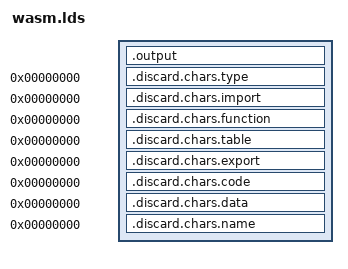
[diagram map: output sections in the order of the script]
SECTIONS
{
  .output : {
    LONG(0x6d736100)
    LONG(11)
    wasm-headers.o(.wasm.header.type); BYTE((((__wasm_type_payload_end - __wasm_type_payload)>>0*7)&0x7f)|0x80); BYTE((((__wasm_type_payload_end - __wasm_type_payload)>>1*7)&0x7f)|0x80); BYTE((((__wasm_type_payload_end - __wasm_type_payload)>>2*7)&0x7f)|0x80); BYTE((((__wasm_type_payload_end - __wasm_type_payload)>>3*7)&0x7f)|0x80); BYTE((((__wasm_type_payload_end - __wasm_type_payload)>>4*7)&0x7f)|0x80); BYTE((((__wasm_type_payload_end - __wasm_type_payload)>>5*7)&0x7f)|0x80); BYTE((((__wasm_type_payload_end - __wasm_type_payload)>>6*7)&0x7f)|0x80); BYTE((((__wasm_type_payload_end - __wasm_type_payload)>>7*7)&0x7f)|0x80); BYTE((((__wasm_type_payload_end - __wasm_type_payload)>>8*7)&0x7f)|0x80); BYTE((((__wasm_type_payload_end - __wasm_type_payload)>>9*7)&0x7f)|0x80); BYTE(0x80); BYTE(0x80); BYTE(0x80); BYTE(0x80); BYTE(0x80); BYTE(0x00);; __wasm_type_payload = .; BYTE((((__wasm_chars_type_end - __wasm_chars_type)>>0*7)&0x7f)|0x80); BYTE((((__wasm_chars_type_end - __wasm_chars_type)>>1*7)&0x7f)|0x80); BYTE((((__wasm_chars_type_end - __wasm_chars_type)>>2*7)&0x7f)|0x80); BYTE((((__wasm_chars_type_end - __wasm_chars_type)>>3*7)&0x7f)|0x80); BYTE((((__wasm_chars_type_end - __wasm_chars_type)>>4*7)&0x7f)|0x80); BYTE((((__wasm_chars_type_end - __wasm_chars_type)>>5*7)&0x7f)|0x80); BYTE((((__wasm_chars_type_end - __wasm_chars_type)>>6*7)&0x7f)|0x80); BYTE((((__wasm_chars_type_end - __wasm_chars_type)>>7*7)&0x7f)|0x80); BYTE((((__wasm_chars_type_end - __wasm_chars_type)>>8*7)&0x7f)|0x80); BYTE((((__wasm_chars_type_end - __wasm_chars_type)>>9*7)&0x7f)|0x80); BYTE(0x80); BYTE(0x80); BYTE(0x80); BYTE(0x80); BYTE(0x80); BYTE(0x00);; *(.wasm.payload.type*); __wasm_type_payload_end = .;
    wasm-headers.o(.wasm.header.import); BYTE((((__wasm_import_payload_end - __wasm_import_payload)>>0*7)&0x7f)|0x80); BYTE((((__wasm_import_payload_end - __wasm_import_payload)>>1*7)&0x7f)|0x80); BYTE((((__wasm_import_payload_end - __wasm_import_payload)>>2*7)&0x7f)|0x80); BYTE((((__wasm_import_payload_end - __wasm_import_payload)>>3*7)&0x7f)|0x80); BYTE((((__wasm_import_payload_end - __wasm_import_payload)>>4*7)&0x7f)|0x80); BYTE((((__wasm_import_payload_end - __wasm_import_payload)>>5*7)&0x7f)|0x80); BYTE((((__wasm_import_payload_end - __wasm_import_payload)>>6*7)&0x7f)|0x80); BYTE((((__wasm_import_payload_end - __wasm_import_payload)>>7*7)&0x7f)|0x80); BYTE((((__wasm_import_payload_end - __wasm_import_payload)>>8*7)&0x7f)|0x80); BYTE((((__wasm_import_payload_end - __wasm_import_payload)>>9*7)&0x7f)|0x80); BYTE(0x80); BYTE(0x80); BYTE(0x80); BYTE(0x80); BYTE(0x80); BYTE(0x00);; __wasm_import_payload = .; BYTE((((__wasm_chars_import_end - __wasm_chars_import)>>0*7)&0x7f)|0x80); BYTE((((__wasm_chars_import_end - __wasm_chars_import)>>1*7)&0x7f)|0x80); BYTE((((__wasm_chars_import_end - __wasm_chars_import)>>2*7)&0x7f)|0x80); BYTE((((__wasm_chars_import_end - __wasm_chars_import)>>3*7)&0x7f)|0x80); BYTE((((__wasm_chars_import_end - __wasm_chars_import)>>4*7)&0x7f)|0x80); BYTE((((__wasm_chars_import_end - __wasm_chars_import)>>5*7)&0x7f)|0x80); BYTE((((__wasm_chars_import_end - __wasm_chars_import)>>6*7)&0x7f)|0x80); BYTE((((__wasm_chars_import_end - __wasm_chars_import)>>7*7)&0x7f)|0x80); BYTE((((__wasm_chars_import_end - __wasm_chars_import)>>8*7)&0x7f)|0x80); BYTE((((__wasm_chars_import_end - __wasm_chars_import)>>9*7)&0x7f)|0x80); BYTE(0x80); BYTE(0x80); BYTE(0x80); BYTE(0x80); BYTE(0x80); BYTE(0x00);; *(.wasm.payload.import*); __wasm_import_payload_end = .;
    wasm-headers.o(.wasm.header.function); BYTE((((__wasm_function_payload_end - __wasm_function_payload)>>0*7)&0x7f)|0x80); BYTE((((__wasm_function_payload_end - __wasm_function_payload)>>1*7)&0x7f)|0x80); BYTE((((__wasm_function_payload_end - __wasm_function_payload)>>2*7)&0x7f)|0x80); BYTE((((__wasm_function_payload_end - __wasm_function_payload)>>3*7)&0x7f)|0x80); BYTE((((__wasm_function_payload_end - __wasm_function_payload)>>4*7)&0x7f)|0x80); BYTE((((__wasm_function_payload_end - __wasm_function_payload)>>5*7)&0x7f)|0x80); BYTE((((__wasm_function_payload_end - __wasm_function_payload)>>6*7)&0x7f)|0x80); BYTE((((__wasm_function_payload_end - __wasm_function_payload)>>7*7)&0x7f)|0x80); BYTE((((__wasm_function_payload_end - __wasm_function_payload)>>8*7)&0x7f)|0x80); BYTE((((__wasm_function_payload_end - __wasm_function_payload)>>9*7)&0x7f)|0x80); BYTE(0x80); BYTE(0x80); BYTE(0x80); BYTE(0x80); BYTE(0x80); BYTE(0x00);; __wasm_function_payload = .; BYTE((((__wasm_chars_function_end - __wasm_chars_function)>>0*7)&0x7f)|0x80); BYTE((((__wasm_chars_function_end - __wasm_chars_function)>>1*7)&0x7f)|0x80); BYTE((((__wasm_chars_function_end - __wasm_chars_function)>>2*7)&0x7f)|0x80); BYTE((((__wasm_chars_function_end - __wasm_chars_function)>>3*7)&0x7f)|0x80); BYTE((((__wasm_chars_function_end - __wasm_chars_function)>>4*7)&0x7f)|0x80); BYTE((((__wasm_chars_function_end - __wasm_chars_function)>>5*7)&0x7f)|0x80); BYTE((((__wasm_chars_function_end - __wasm_chars_function)>>6*7)&0x7f)|0x80); BYTE((((__wasm_chars_function_end - __wasm_chars_function)>>7*7)&0x7f)|0x80); BYTE((((__wasm_chars_function_end - __wasm_chars_function)>>8*7)&0x7f)|0x80); BYTE((((__wasm_chars_function_end - __wasm_chars_function)>>9*7)&0x7f)|0x80); BYTE(0x80); BYTE(0x80); BYTE(0x80); BYTE(0x80); BYTE(0x80); BYTE(0x00);; *(.wasm.payload.function*); __wasm_function_payload_end = .;
    wasm-headers.o(.wasm.header.table); BYTE((((__wasm_table_payload_end - __wasm_table_payload)>>0*7)&0x7f)|0x80); BYTE((((__wasm_table_payload_end - __wasm_table_payload)>>1*7)&0x7f)|0x80); BYTE((((__wasm_table_payload_end - __wasm_table_payload)>>2*7)&0x7f)|0x80); BYTE((((__wasm_table_payload_end - __wasm_table_payload)>>3*7)&0x7f)|0x80); BYTE((((__wasm_table_payload_end - __wasm_table_payload)>>4*7)&0x7f)|0x80); BYTE((((__wasm_table_payload_end - __wasm_table_payload)>>5*7)&0x7f)|0x80); BYTE((((__wasm_table_payload_end - __wasm_table_payload)>>6*7)&0x7f)|0x80); BYTE((((__wasm_table_payload_end - __wasm_table_payload)>>7*7)&0x7f)|0x80); BYTE((((__wasm_table_payload_end - __wasm_table_payload)>>8*7)&0x7f)|0x80); BYTE((((__wasm_table_payload_end - __wasm_table_payload)>>9*7)&0x7f)|0x80); BYTE(0x80); BYTE(0x80); BYTE(0x80); BYTE(0x80); BYTE(0x80); BYTE(0x00);; __wasm_table_payload = .; BYTE((((__wasm_chars_table_end - __wasm_chars_table)>>0*7)&0x7f)|0x80); BYTE((((__wasm_chars_table_end - __wasm_chars_table)>>1*7)&0x7f)|0x80); BYTE((((__wasm_chars_table_end - __wasm_chars_table)>>2*7)&0x7f)|0x80); BYTE((((__wasm_chars_table_end - __wasm_chars_table)>>3*7)&0x7f)|0x80); BYTE((((__wasm_chars_table_end - __wasm_chars_table)>>4*7)&0x7f)|0x80); BYTE((((__wasm_chars_table_end - __wasm_chars_table)>>5*7)&0x7f)|0x80); BYTE((((__wasm_chars_table_end - __wasm_chars_table)>>6*7)&0x7f)|0x80); BYTE((((__wasm_chars_table_end - __wasm_chars_table)>>7*7)&0x7f)|0x80); BYTE((((__wasm_chars_table_end - __wasm_chars_table)>>8*7)&0x7f)|0x80); BYTE((((__wasm_chars_table_end - __wasm_chars_table)>>9*7)&0x7f)|0x80); BYTE(0x80); BYTE(0x80); BYTE(0x80); BYTE(0x80); BYTE(0x80); BYTE(0x00);; *(.wasm.payload.table*); __wasm_table_payload_end = .;
    wasm-headers.o(.wasm.header.memory); BYTE((((__wasm_memory_payload_end - __wasm_memory_payload)>>0*7)&0x7f)|0x80); BYTE((((__wasm_memory_payload_end - __wasm_memory_payload)>>1*7)&0x7f)|0x80); BYTE((((__wasm_memory_payload_end - __wasm_memory_payload)>>2*7)&0x7f)|0x80); BYTE((((__wasm_memory_payload_end - __wasm_memory_payload)>>3*7)&0x7f)|0x80); BYTE((((__wasm_memory_payload_end - __wasm_memory_payload)>>4*7)&0x7f)|0x80); BYTE((((__wasm_memory_payload_end - __wasm_memory_payload)>>5*7)&0x7f)|0x80); BYTE((((__wasm_memory_payload_end - __wasm_memory_payload)>>6*7)&0x7f)|0x80); BYTE((((__wasm_memory_payload_end - __wasm_memory_payload)>>7*7)&0x7f)|0x80); BYTE((((__wasm_memory_payload_end - __wasm_memory_payload)>>8*7)&0x7f)|0x80); BYTE((((__wasm_memory_payload_end - __wasm_memory_payload)>>9*7)&0x7f)|0x80); BYTE(0x80); BYTE(0x80); BYTE(0x80); BYTE(0x80); BYTE(0x80); BYTE(0x00);; __wasm_memory_payload = .; LONG(0x0080c080); LONG(0x0080c080); BYTE(1);; *(.wasm.payload.memory*); __wasm_memory_payload_end = .;
    wasm-headers.o(.wasm.header.export); BYTE((((__wasm_export_payload_end - __wasm_export_payload)>>0*7)&0x7f)|0x80); BYTE((((__wasm_export_payload_end - __wasm_export_payload)>>1*7)&0x7f)|0x80); BYTE((((__wasm_export_payload_end - __wasm_export_payload)>>2*7)&0x7f)|0x80); BYTE((((__wasm_export_payload_end - __wasm_export_payload)>>3*7)&0x7f)|0x80); BYTE((((__wasm_export_payload_end - __wasm_export_payload)>>4*7)&0x7f)|0x80); BYTE((((__wasm_export_payload_end - __wasm_export_payload)>>5*7)&0x7f)|0x80); BYTE((((__wasm_export_payload_end - __wasm_export_payload)>>6*7)&0x7f)|0x80); BYTE((((__wasm_export_payload_end - __wasm_export_payload)>>7*7)&0x7f)|0x80); BYTE((((__wasm_export_payload_end - __wasm_export_payload)>>8*7)&0x7f)|0x80); BYTE((((__wasm_export_payload_end - __wasm_export_payload)>>9*7)&0x7f)|0x80); BYTE(0x80); BYTE(0x80); BYTE(0x80); BYTE(0x80); BYTE(0x80); BYTE(0x00);; __wasm_export_payload = .; BYTE((((__wasm_chars_export_end - __wasm_chars_export)>>0*7)&0x7f)|0x80); BYTE((((__wasm_chars_export_end - __wasm_chars_export)>>1*7)&0x7f)|0x80); BYTE((((__wasm_chars_export_end - __wasm_chars_export)>>2*7)&0x7f)|0x80); BYTE((((__wasm_chars_export_end - __wasm_chars_export)>>3*7)&0x7f)|0x80); BYTE((((__wasm_chars_export_end - __wasm_chars_export)>>4*7)&0x7f)|0x80); BYTE((((__wasm_chars_export_end - __wasm_chars_export)>>5*7)&0x7f)|0x80); BYTE((((__wasm_chars_export_end - __wasm_chars_export)>>6*7)&0x7f)|0x80); BYTE((((__wasm_chars_export_end - __wasm_chars_export)>>7*7)&0x7f)|0x80); BYTE((((__wasm_chars_export_end - __wasm_chars_export)>>8*7)&0x7f)|0x80); BYTE((((__wasm_chars_export_end - __wasm_chars_export)>>9*7)&0x7f)|0x80); BYTE(0x80); BYTE(0x80); BYTE(0x80); BYTE(0x80); BYTE(0x80); BYTE(0x00);; *(.wasm.payload.export*); __wasm_export_payload_end = .;
    wasm-headers.o(.wasm.header.code); BYTE((((__wasm_code_payload_end - __wasm_code_payload)>>0*7)&0x7f)|0x80); BYTE((((__wasm_code_payload_end - __wasm_code_payload)>>1*7)&0x7f)|0x80); BYTE((((__wasm_code_payload_end - __wasm_code_payload)>>2*7)&0x7f)|0x80); BYTE((((__wasm_code_payload_end - __wasm_code_payload)>>3*7)&0x7f)|0x80); BYTE((((__wasm_code_payload_end - __wasm_code_payload)>>4*7)&0x7f)|0x80); BYTE((((__wasm_code_payload_end - __wasm_code_payload)>>5*7)&0x7f)|0x80); BYTE((((__wasm_code_payload_end - __wasm_code_payload)>>6*7)&0x7f)|0x80); BYTE((((__wasm_code_payload_end - __wasm_code_payload)>>7*7)&0x7f)|0x80); BYTE((((__wasm_code_payload_end - __wasm_code_payload)>>8*7)&0x7f)|0x80); BYTE((((__wasm_code_payload_end - __wasm_code_payload)>>9*7)&0x7f)|0x80); BYTE(0x80); BYTE(0x80); BYTE(0x80); BYTE(0x80); BYTE(0x80); BYTE(0x00);; __wasm_code_payload = .; BYTE((((__wasm_chars_code_end - __wasm_chars_code)>>0*7)&0x7f)|0x80); BYTE((((__wasm_chars_code_end - __wasm_chars_code)>>1*7)&0x7f)|0x80); BYTE((((__wasm_chars_code_end - __wasm_chars_code)>>2*7)&0x7f)|0x80); BYTE((((__wasm_chars_code_end - __wasm_chars_code)>>3*7)&0x7f)|0x80); BYTE((((__wasm_chars_code_end - __wasm_chars_code)>>4*7)&0x7f)|0x80); BYTE((((__wasm_chars_code_end - __wasm_chars_code)>>5*7)&0x7f)|0x80); BYTE((((__wasm_chars_code_end - __wasm_chars_code)>>6*7)&0x7f)|0x80); BYTE((((__wasm_chars_code_end - __wasm_chars_code)>>7*7)&0x7f)|0x80); BYTE((((__wasm_chars_code_end - __wasm_chars_code)>>8*7)&0x7f)|0x80); BYTE((((__wasm_chars_code_end - __wasm_chars_code)>>9*7)&0x7f)|0x80); BYTE(0x80); BYTE(0x80); BYTE(0x80); BYTE(0x80); BYTE(0x80); BYTE(0x00);; *(.wasm.payload.code*); __wasm_code_payload_end = .;
    wasm-headers.o(.wasm.header.start); BYTE((((__wasm_start_payload_end - __wasm_start_payload)>>0*7)&0x7f)|0x80); BYTE((((__wasm_start_payload_end - __wasm_start_payload)>>1*7)&0x7f)|0x80); BYTE((((__wasm_start_payload_end - __wasm_start_payload)>>2*7)&0x7f)|0x80); BYTE((((__wasm_start_payload_end - __wasm_start_payload)>>3*7)&0x7f)|0x80); BYTE((((__wasm_start_payload_end - __wasm_start_payload)>>4*7)&0x7f)|0x80); BYTE((((__wasm_start_payload_end - __wasm_start_payload)>>5*7)&0x7f)|0x80); BYTE((((__wasm_start_payload_end - __wasm_start_payload)>>6*7)&0x7f)|0x80); BYTE((((__wasm_start_payload_end - __wasm_start_payload)>>7*7)&0x7f)|0x80); BYTE((((__wasm_start_payload_end - __wasm_start_payload)>>8*7)&0x7f)|0x80); BYTE((((__wasm_start_payload_end - __wasm_start_payload)>>9*7)&0x7f)|0x80); BYTE(0x80); BYTE(0x80); BYTE(0x80); BYTE(0x80); BYTE(0x80); BYTE(0x00);; __wasm_start_payload = .; BYTE((((_start)>>0*7)&0x7f)|0x80); BYTE((((_start)>>1*7)&0x7f)|0x80); BYTE((((_start)>>2*7)&0x7f)|0x80); BYTE((((_start)>>3*7)&0x7f)|0x80); BYTE((((_start)>>4*7)&0x7f)|0x80); BYTE((((_start)>>5*7)&0x7f)|0x80); BYTE((((_start)>>6*7)&0x7f)|0x80); BYTE((((_start)>>7*7)&0x7f)|0x80); BYTE((((_start)>>8*7)&0x7f)|0x80); BYTE((((_start)>>9*7)&0x7f)|0x80); BYTE(0x80); BYTE(0x80); BYTE(0x80); BYTE(0x80); BYTE(0x80); BYTE(0x00);; *(.wasm.payload.start*); __wasm_start_payload_end = .;
    wasm-headers.o(.wasm.header.data); BYTE((((__wasm_data_payload_end - __wasm_data_payload)>>0*7)&0x7f)|0x80); BYTE((((__wasm_data_payload_end - __wasm_data_payload)>>1*7)&0x7f)|0x80); BYTE((((__wasm_data_payload_end - __wasm_data_payload)>>2*7)&0x7f)|0x80); BYTE((((__wasm_data_payload_end - __wasm_data_payload)>>3*7)&0x7f)|0x80); BYTE((((__wasm_data_payload_end - __wasm_data_payload)>>4*7)&0x7f)|0x80); BYTE((((__wasm_data_payload_end - __wasm_data_payload)>>5*7)&0x7f)|0x80); BYTE((((__wasm_data_payload_end - __wasm_data_payload)>>6*7)&0x7f)|0x80); BYTE((((__wasm_data_payload_end - __wasm_data_payload)>>7*7)&0x7f)|0x80); BYTE((((__wasm_data_payload_end - __wasm_data_payload)>>8*7)&0x7f)|0x80); BYTE((((__wasm_data_payload_end - __wasm_data_payload)>>9*7)&0x7f)|0x80); BYTE(0x80); BYTE(0x80); BYTE(0x80); BYTE(0x80); BYTE(0x80); BYTE(0x00);; __wasm_data_payload = .; BYTE((((__wasm_chars_data_end - __wasm_chars_data)>>0*7)&0x7f)|0x80); BYTE((((__wasm_chars_data_end - __wasm_chars_data)>>1*7)&0x7f)|0x80); BYTE((((__wasm_chars_data_end - __wasm_chars_data)>>2*7)&0x7f)|0x80); BYTE((((__wasm_chars_data_end - __wasm_chars_data)>>3*7)&0x7f)|0x80); BYTE((((__wasm_chars_data_end - __wasm_chars_data)>>4*7)&0x7f)|0x80); BYTE((((__wasm_chars_data_end - __wasm_chars_data)>>5*7)&0x7f)|0x80); BYTE((((__wasm_chars_data_end - __wasm_chars_data)>>6*7)&0x7f)|0x80); BYTE((((__wasm_chars_data_end - __wasm_chars_data)>>7*7)&0x7f)|0x80); BYTE((((__wasm_chars_data_end - __wasm_chars_data)>>8*7)&0x7f)|0x80); BYTE((((__wasm_chars_data_end - __wasm_chars_data)>>9*7)&0x7f)|0x80); BYTE(0x80); BYTE(0x80); BYTE(0x80); BYTE(0x80); BYTE(0x80); BYTE(0x00);; *(.wasm.payload.data*); __wasm_data_payload_end = .;
    wasm-headers.o(.wasm.header.name); BYTE((((__wasm_name_payload_end - __wasm_name_payload)>>0*7)&0x7f)|0x80); BYTE((((__wasm_name_payload_end - __wasm_name_payload)>>1*7)&0x7f)|0x80); BYTE((((__wasm_name_payload_end - __wasm_name_payload)>>2*7)&0x7f)|0x80); BYTE((((__wasm_name_payload_end - __wasm_name_payload)>>3*7)&0x7f)|0x80); BYTE((((__wasm_name_payload_end - __wasm_name_payload)>>4*7)&0x7f)|0x80); BYTE((((__wasm_name_payload_end - __wasm_name_payload)>>5*7)&0x7f)|0x80); BYTE((((__wasm_name_payload_end - __wasm_name_payload)>>6*7)&0x7f)|0x80); BYTE((((__wasm_name_payload_end - __wasm_name_payload)>>7*7)&0x7f)|0x80); BYTE((((__wasm_name_payload_end - __wasm_name_payload)>>8*7)&0x7f)|0x80); BYTE((((__wasm_name_payload_end - __wasm_name_payload)>>9*7)&0x7f)|0x80); BYTE(0x80); BYTE(0x80); BYTE(0x80); BYTE(0x80); BYTE(0x80); BYTE(0x00);; __wasm_name_payload = .; BYTE((((__wasm_chars_name_end - __wasm_chars_name)>>0*7)&0x7f)|0x80); BYTE((((__wasm_chars_name_end - __wasm_chars_name)>>1*7)&0x7f)|0x80); BYTE((((__wasm_chars_name_end - __wasm_chars_name)>>2*7)&0x7f)|0x80); BYTE((((__wasm_chars_name_end - __wasm_chars_name)>>3*7)&0x7f)|0x80); BYTE((((__wasm_chars_name_end - __wasm_chars_name)>>4*7)&0x7f)|0x80); BYTE((((__wasm_chars_name_end - __wasm_chars_name)>>5*7)&0x7f)|0x80); BYTE((((__wasm_chars_name_end - __wasm_chars_name)>>6*7)&0x7f)|0x80); BYTE((((__wasm_chars_name_end - __wasm_chars_name)>>7*7)&0x7f)|0x80); BYTE((((__wasm_chars_name_end - __wasm_chars_name)>>8*7)&0x7f)|0x80); BYTE((((__wasm_chars_name_end - __wasm_chars_name)>>9*7)&0x7f)|0x80); BYTE(0x80); BYTE(0x80); BYTE(0x80); BYTE(0x80); BYTE(0x80); BYTE(0x00);; *(.wasm.payload.name*); __wasm_name_payload_end = .;
  }
  .discard.chars.type 0 : { . = 0; __wasm_chars_type = .; *(.wasm.chars.type*); __wasm_chars_type_end = .; }
  .discard.chars.import 0 : { . = 0; __wasm_chars_import = .; *(.wasm.chars.import*); __wasm_chars_import_end = .; }
  .discard.chars.function 0 : { . = 0; __wasm_chars_function = .; *(.wasm.chars.function*); __wasm_chars_function_end = .; }
  .discard.chars.table 0 : { . = 0; __wasm_chars_table = .; *(.wasm.chars.table*); __wasm_chars_table_end = .; }
  .discard.chars.export 0 : { . = 0; __wasm_chars_export = .; *(.wasm.chars.export*); __wasm_chars_export_end = .; }
  .discard.chars.code 0 : { . = 0; __wasm_chars_code = .; *(.wasm.chars.code*); __wasm_chars_code_end = .; }
  .discard.chars.data 0 : { . = 0; __wasm_chars_data = .; *(.wasm.chars.data*); __wasm_chars_data_end = .; }
  .discard.chars.name 0 : { . = 0; __wasm_chars_name = .; *(.wasm.chars.name*); __wasm_chars_name_end = .; }
  /DISCARD/ : {
    *(*)
  }
}
